# STM32MP153 register map
File version: 1.3
CPU: CM4 r0p1, little endian, no MPU, FPU, 4 interrupt priority bits
Registers are 32-bit, read-write, reset 0x0 unless marked. A register's access mark holds for its fields unless they carry their own. Offsets are from the block's base; [hi:lo] are bit positions; {n}, {i} and the like mark numbered series.

## AXIMC_Mx
Base 0x57042024
{0x0+0x1000*i} AXIMC_M{i}_FN_MOD2 (i=0..2) — AXIMC master {i} packing functionality register
  [0] BYPASS_MERGE
{0xDC+0x1000*i} AXIMC_M{i}_READ_QOS reset 0x6 (i=0..2) — AXIMC master {i} read priority register
  [3:0] AR_QOS
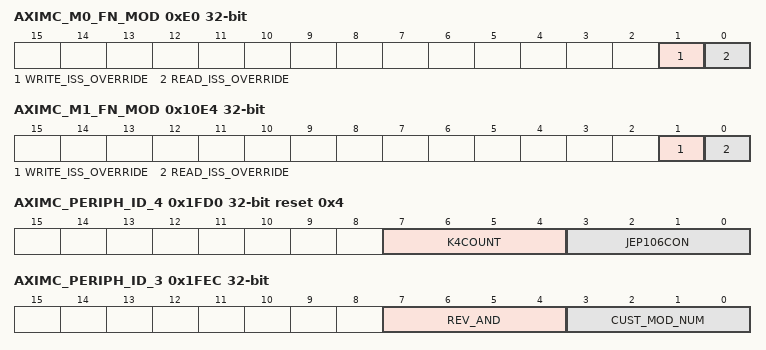
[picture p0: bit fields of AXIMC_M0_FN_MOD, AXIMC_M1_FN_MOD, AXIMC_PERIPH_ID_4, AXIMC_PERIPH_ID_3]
0xE0 AXIMC_M0_FN_MOD — AXIMC master 0 issuing capability override functionality register
  [1] WRITE_ISS_OVERRIDE, [0] READ_ISS_OVERRIDE
0xE4 AXIMC_M0_WRITE_QOS reset 0x6 — AXIMC master 0 write priority register
  [3:0] AW_QOS
0x10E0 AXIMC_M1_WRITE_QOS reset 0x6 — AXIMC master 1 write priority register
  [3:0] AW_QOS
0x10E4 AXIMC_M1_FN_MOD — AXIMC master 1 issuing capability override functionality register
  [1] WRITE_ISS_OVERRIDE, [0] READ_ISS_OVERRIDE
0x1FD0 AXIMC_PERIPH_ID_4 ro reset 0x4 — AXIMC peripheral ID4 register
  [7:4] K4COUNT, [3:0] JEP106CON
{0x1FC0+4i} AXIMC_PERIPH_ID_{i} ro (i=5..7) — AXIMC peripheral ID{i} register
  [7:0] PERIPH_ID_{i}
0x1FE0 AXIMC_PERIPH_ID_0 ro — AXIMC peripheral ID0 register
  [7:0] PERIPH_ID_0
0x1FE4 AXIMC_PERIPH_ID_1 ro reset 0xB4 — AXIMC peripheral ID1 register
  [7:0] PERIPH_ID_1
0x1FE8 AXIMC_PERIPH_ID_2 ro reset 0x3B — AXIMC peripheral ID2 register
  [7:0] PERIPH_ID_2
0x1FEC AXIMC_PERIPH_ID_3 ro — AXIMC peripheral ID3 register
  [7:4] REV_AND, [3:0] CUST_MOD_NUM
0x1FF0 AXIMC_COMP_ID_0 ro reset 0xD — AXIMC component ID0 register
  [7:0] PREAMBLE
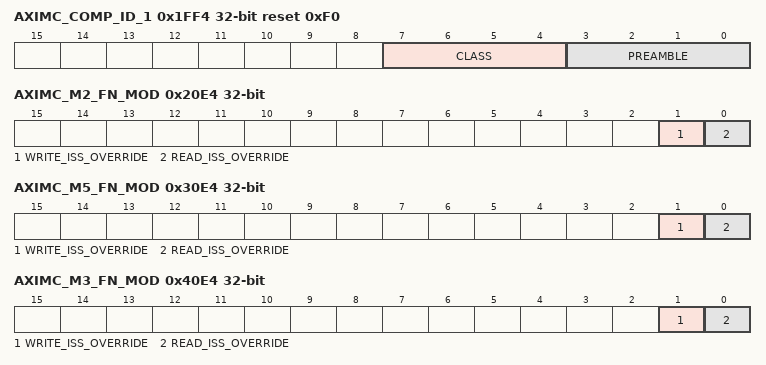
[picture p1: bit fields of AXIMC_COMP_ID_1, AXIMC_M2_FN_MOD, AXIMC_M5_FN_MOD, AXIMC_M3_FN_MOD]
0x1FF4 AXIMC_COMP_ID_1 ro reset 0xF0 — AXIMC component ID1 register
  [7:4] CLASS, [3:0] PREAMBLE
0x1FF8 AXIMC_COMP_ID_2 ro reset 0x5 — AXIMC component ID2 register
  [7:0] PREAMBLE
0x1FFC AXIMC_COMP_ID_3 ro reset 0xB1 — AXIMC component ID3 register
  [7:0] PREAMBLE
0x20E0 AXIMC_M2_WRITE_QOS reset 0x6 — AXIMC master 2 write priority register
  [3:0] AW_QOS
0x20E4 AXIMC_M2_FN_MOD — AXIMC master 2 issuing capability override functionality register
  [1] WRITE_ISS_OVERRIDE, [0] READ_ISS_OVERRIDE
0x3000 AXIMC_M5_FN_MOD2 — AXIMC master 5 packing functionality register
  [0] BYPASS_MERGE
0x30DC AXIMC_M5_READ_QOS reset 0x4 — AXIMC master 5 read priority register
  [3:0] AR_QOS
0x30E0 AXIMC_M5_WRITE_QOS reset 0x4 — AXIMC master 5 write priority register
  [3:0] AW_QOS
0x30E4 AXIMC_M5_FN_MOD — AXIMC master 5 issuing capability override functionality register
  [1] WRITE_ISS_OVERRIDE, [0] READ_ISS_OVERRIDE
0x40DC AXIMC_M3_READ_QOS reset 0x7 — AXIMC master 3 read priority register
  [3:0] AR_QOS
0x40E0 AXIMC_M3_WRITE_QOS reset 0x7 — AXIMC master 3 write priority register
  [3:0] AW_QOS
0x40E4 AXIMC_M3_FN_MOD — AXIMC master 3 packing functionality register
  [1] WRITE_ISS_OVERRIDE, [0] READ_ISS_OVERRIDE
0x50DC AXIMC_M7_READ_QOS reset 0x8 — AXIMC master 7 read priority register
  [3:0] AR_QOS
0x50E0 AXIMC_M7_WRITE_QOS reset 0x8 — AXIMC master 7 write priority register
  [3:0] AW_QOS
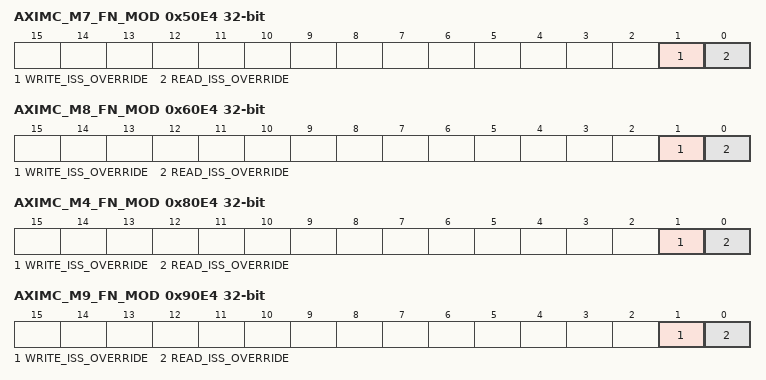
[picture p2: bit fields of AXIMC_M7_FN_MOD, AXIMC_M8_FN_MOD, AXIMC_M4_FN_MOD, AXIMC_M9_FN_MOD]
0x50E4 AXIMC_M7_FN_MOD — AXIMC master 7 issuing capability override functionality register
  [1] WRITE_ISS_OVERRIDE, [0] READ_ISS_OVERRIDE
0x60DC AXIMC_M8_READ_QOS reset 0x8 — AXIMC master 8 read priority register
  [3:0] AR_QOS
0x60E0 AXIMC_M8_WRITE_QOS reset 0x8 — AXIMC master 8 write priority register
  [3:0] AW_QOS
0x60E4 AXIMC_M8_FN_MOD — AXIMC master 8 issuing capability override functionality register
  [1] WRITE_ISS_OVERRIDE, [0] READ_ISS_OVERRIDE
0x8000 AXIMC_M4_FN_MOD2 — AXIMC master 4 packing functionality register
  [0] BYPASS_MERGE
0x80DC AXIMC_M4_READ_QOS reset 0x7 — AXIMC master 4 read priority register
  [3:0] AR_QOS
0x80E0 AXIMC_M4_WRITE_QOS reset 0x7 — AXIMC master 4 write priority register
  [3:0] AW_QOS
0x80E4 AXIMC_M4_FN_MOD — AXIMC master 4 packing functionality register
  [1] WRITE_ISS_OVERRIDE, [0] READ_ISS_OVERRIDE
0x90DC AXIMC_M9_READ_QOS reset 0xB — AXIMC master 9 read priority register
  [3:0] AR_QOS
0x90E0 AXIMC_M9_WRITE_QOS reset 0xB — AXIMC master 9 write priority register
  [3:0] AW_QOS
0x90E4 AXIMC_M9_FN_MOD — AXIMC master 9 issuing capability override functionality register
  [1] WRITE_ISS_OVERRIDE, [0] READ_ISS_OVERRIDE
0xA0DC AXIMC_M10_READ_QOS reset 0xB — AXIMC master 10 read priority register
  [3:0] AR_QOS
0xA0E0 AXIMC_M10_WRITE_QOS reset 0xB — AXIMC master 10 write priority register
  [3:0] AW_QOS
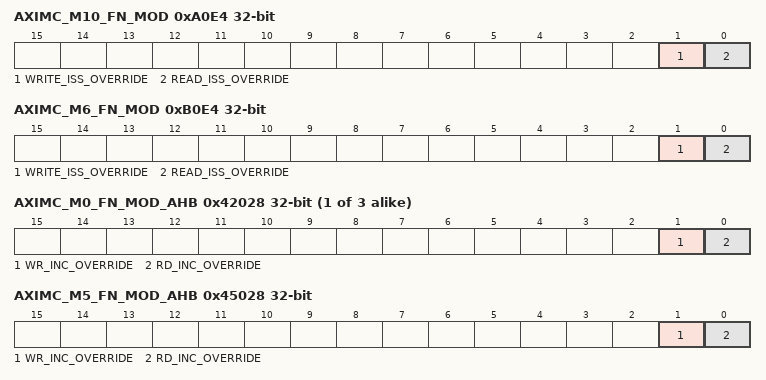
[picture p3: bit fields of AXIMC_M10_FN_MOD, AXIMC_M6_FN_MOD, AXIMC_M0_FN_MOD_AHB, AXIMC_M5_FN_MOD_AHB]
0xA0E4 AXIMC_M10_FN_MOD — AXIMC master 10 issuing capability override functionality register
  [1] WRITE_ISS_OVERRIDE, [0] READ_ISS_OVERRIDE
0xB000 AXIMC_M6_FN_MOD2 — AXIMC master 6 packing functionality register
  [0] BYPASS_MERGE
0xB0DC AXIMC_M6_READ_QOS reset 0x4 — AXIMC master 6 read priority register
  [3:0] AR_QOS
0xB0E0 AXIMC_M6_WRITE_QOS reset 0x4 — AXIMC master 6 write priority register
  [3:0] AW_QOS
0xB0E4 AXIMC_M6_FN_MOD — AXIMC master 6 issuing capability override functionality register
  [1] WRITE_ISS_OVERRIDE, [0] READ_ISS_OVERRIDE
{0x42028+0x1000*i} AXIMC_M{i}_FN_MOD_AHB (i=0..2) — AXIMC master {i} AHB conversion override functionality register
  [1] WR_INC_OVERRIDE, [0] RD_INC_OVERRIDE
0x45028 AXIMC_M5_FN_MOD_AHB — AXIMC master 5 AHB conversion override functionality register
  [1] WR_INC_OVERRIDE, [0] RD_INC_OVERRIDE
0x4A02C AXIMC_FN_MOD_LB — AXIMC long burst capability inhibition register
  [0] FN_MOD_LB
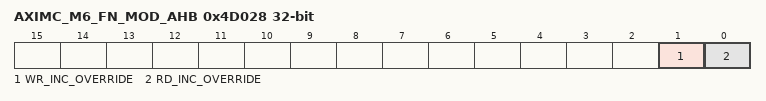
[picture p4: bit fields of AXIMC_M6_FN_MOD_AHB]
0x4D028 AXIMC_M6_FN_MOD_AHB — AXIMC master 6 AHB conversion override functionality register
  [1] WR_INC_OVERRIDE, [0] RD_INC_OVERRIDE
